# DECODER0_MSVDX_VEC_VC1 register map
Vendor: Texas Instruments
Peripheral module from a debugger description file (folder J7ES).
Registers are 32-bit, read-write, reset 0x0 unless marked. A register's access mark holds for its fields unless they carry their own. Offsets are as the file gives them; lines under a group give offsets from that group; [hi:lo] are bit positions; {n}, {i} and the like mark numbered series; 'fields as' and 'values as' point back to an identical list; <NAME> marks a mode.

## DECODER0_MSVDX_VEC_VC1
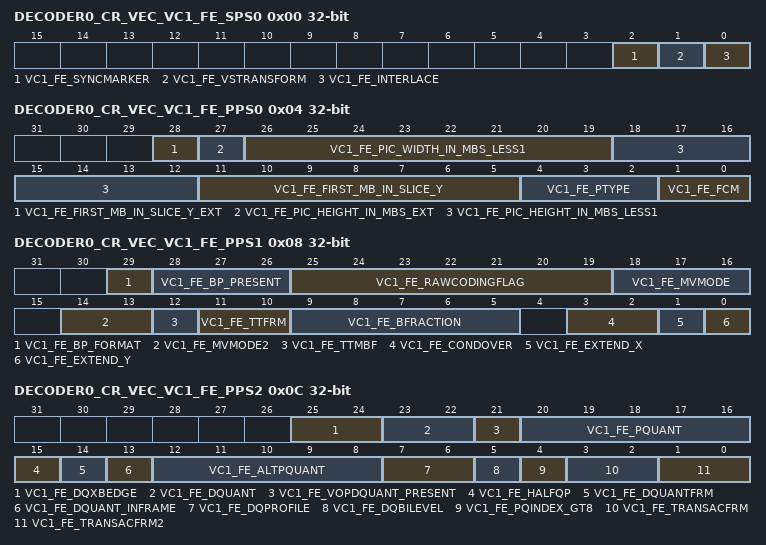
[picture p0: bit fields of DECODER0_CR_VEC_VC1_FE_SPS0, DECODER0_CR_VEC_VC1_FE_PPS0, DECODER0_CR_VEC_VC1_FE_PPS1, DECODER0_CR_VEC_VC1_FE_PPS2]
0x00 DECODER0_CR_VEC_VC1_FE_SPS0
  [2] VC1_FE_SYNCMARKER — Syncmarker Flag
  [1] VC1_FE_VSTRANSFORM — Variable Sized Transform Flag
  [0] VC1_FE_INTERLACE — Interlace Content [INTERLACE] [1 bit]
0x04 DECODER0_CR_VEC_VC1_FE_PPS0
  [28] VC1_FE_FIRST_MB_IN_SLICE_Y_EXT — Extension to VC1_FE_FIRST_MB_IN_SLICE_Y to allow for 4k x 4k resolution
  [27] VC1_FE_PIC_HEIGHT_IN_MBS_EXT — Extension to VC1_FE_PIC_HEIGHT_IN_MBS_LESS1 to allow for 4k x 4k resolution
  [26:19] VC1_FE_PIC_WIDTH_IN_MBS_LESS1 — of MBs less 1 across the width of the picture
  [18:12] VC1_FE_PIC_HEIGHT_IN_MBS_LESS1 — Number of MBs less 1 along the height of the picture [field or frame]
  [11:5] VC1_FE_FIRST_MB_IN_SLICE_Y — Slice Address
  [4:2] VC1_FE_PTYPE — Picture Type [PTYPE] [Variable size]
  [1:0] VC1_FE_FCM — Frame Coding Mode
0x08 DECODER0_CR_VEC_VC1_FE_PPS1
  [29] VC1_FE_BP_FORMAT — BP format in memory
  [28:26] VC1_FE_BP_PRESENT — Vector that indicates whether a given bitplane is present in the picture
  [25:19] VC1_FE_RAWCODINGFLAG — Vector that indicates whether a given bitplane is coded in raw mode
  [18:16] VC1_FE_MVMODE — Motion Vector Mode
  [14:13] VC1_FE_MVMODE2 — Motion Vector Mode 2
  [12] VC1_FE_TTMBF — Macroblock-level Transform Type Flag
  [11:10] VC1_FE_TTFRM — Frame-level Transform Type
  [9:5] VC1_FE_BFRACTION — Picture Fraction
  [3:2] VC1_FE_CONDOVER — Conditional Overlap Flag
  [1] VC1_FE_EXTEND_X — Extended Horizontal Differential Motion Vector Range Flag
  [0] VC1_FE_EXTEND_Y — Extended Vertical Differential Motion Vector Range Flag
0x0C DECODER0_CR_VEC_VC1_FE_PPS2
  [25:24] VC1_FE_DQXBEDGE — DQSBEDGE or DQDBEDGE, only one is present at any given instance
  [23:22] VC1_FE_DQUANT — Macroblock Quantization Flag [DQUANT]
  [21] VC1_FE_VOPDQUANT_PRESENT — Indicates whether MB Quantisation is used
  [20:16] VC1_FE_PQUANT — Picture Quantizer Scale [PQUANT]
  [15] VC1_FE_HALFQP — Half QP Step
  [14] VC1_FE_DQUANTFRM — Differential Quantizer Frame
  [13] VC1_FE_DQUANT_INFRAME — Indicates if quantizer can vary between the macroblocks of a frame.
  [12:8] VC1_FE_ALTPQUANT — Alternative Picture quantizer scale, defined by VOPDQUANT parameters, shall be applied to specific areas of the picture [in the same manner as PQUANT] when DQUANTFRM is set
  [7:6] VC1_FE_DQPROFILE — Differential Quantizer Profile [DQPROFILE] [2 bits]
  [5] VC1_FE_DQBILEVEL — Differential Quantizer Binary Level [DQBILEVEL] [1 bit]
  [4] VC1_FE_PQINDEX_GT8 — Flag to represent whether PQINDEX [described below] is greater than 8
  [3:2] VC1_FE_TRANSACFRM — Frame-level Transform AC Coding Set Index
  [1:0] VC1_FE_TRANSACFRM2 — Frame-level Transform AC Table-2 Index
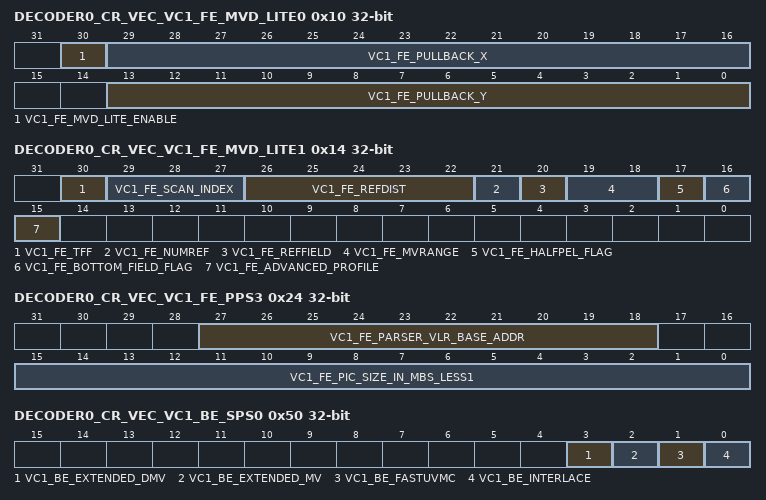
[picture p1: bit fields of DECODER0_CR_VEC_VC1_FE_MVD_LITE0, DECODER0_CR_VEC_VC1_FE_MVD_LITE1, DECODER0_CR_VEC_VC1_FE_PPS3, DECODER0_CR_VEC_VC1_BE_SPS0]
0x10 DECODER0_CR_VEC_VC1_FE_MVD_LITE0
  [30] VC1_FE_MVD_LITE_ENABLE — Flag to indicate whether MVD Lite is to be enabled
  [29:16] VC1_FE_PULLBACK_X — X value for Pullback
  [13:0] VC1_FE_PULLBACK_Y — Y value for Pullback
0x14 DECODER0_CR_VEC_VC1_FE_MVD_LITE1
  [30] VC1_FE_TFF — Top field first indicator
  [29:27] VC1_FE_SCAN_INDEX — Indicates picture type and profile for Inverse Scan to select the set of scan tables to use
  [26:22] VC1_FE_REFDIST — P Reference Distance [REFDIST]
  [21] VC1_FE_NUMREF — Number of Reference Pictures [NUMREF] [1 bit]
  [20] VC1_FE_REFFIELD — Reference Field Picture Indicator [REFFIELD] [1 bit]
  [19:18] VC1_FE_MVRANGE — Extended MV Range Flag [MVRANGE] [Variable size]
  [17] VC1_FE_HALFPEL_FLAG — Indicates the precision used for the MVs in the picture
  [16] VC1_FE_BOTTOM_FIELD_FLAG — Signals bottom field of current picture
  [15] VC1_FE_ADVANCED_PROFILE — Advanced profile flag - needed to check whether end of data implies that there might be extra skipped macroblocks to generate
0x18 DECODER0_CR_VEC_VC1_FE_BITPLANES_BASE_ADDR0
  [31:12] VC1_FE_BITPLANES_BASE_ADDR0 — Base address in the System Memory of Bitplane 0.
0x1C DECODER0_CR_VEC_VC1_FE_BITPLANES_BASE_ADDR1
  [31:12] VC1_FE_BITPLANES_BASE_ADDR1 — Base address in the System RAM of the Bitplane 1.
0x20 DECODER0_CR_VEC_VC1_FE_BITPLANES_BASE_ADDR2
  [31:12] VC1_FE_BITPLANES_BASE_ADDR2 — Base address in the System RAM of the Bitplane 2.
0x24 DECODER0_CR_VEC_VC1_FE_PPS3
  [27:18] VC1_FE_PARSER_VLR_BASE_ADDR — Base address pointer within VEC Local RAM used by VC-1 or MVD-lite or VC-1 bitplane parser.
  [15:0] VC1_FE_PIC_SIZE_IN_MBS_LESS1 — Size of picture in MBs less 1.
0x50 DECODER0_CR_VEC_VC1_BE_SPS0
  [3] VC1_BE_EXTENDED_DMV — Extended Differential Motion Vector Range Flag
  [2] VC1_BE_EXTENDED_MV — Extended Motion Vector Flag
  [1] VC1_BE_FASTUVMC — Fast UV Motion Compensation Flag
  [0] VC1_BE_INTERLACE — Interlace Content
0x54 DECODER0_CR_VEC_VC1_BE_SPS1
  [7:0] VC1_BE_PIC_HEIGHT_IN_MBS_LESS1 — of MBs less 1 along the height of the picture [field or frame]
0x58 DECODER0_CR_VEC_VC1_BE_SPS2
  [7:0] VC1_BE_PIC_WIDTH_IN_MBS_LESS1 — of MBs less 1 across the width of the picture
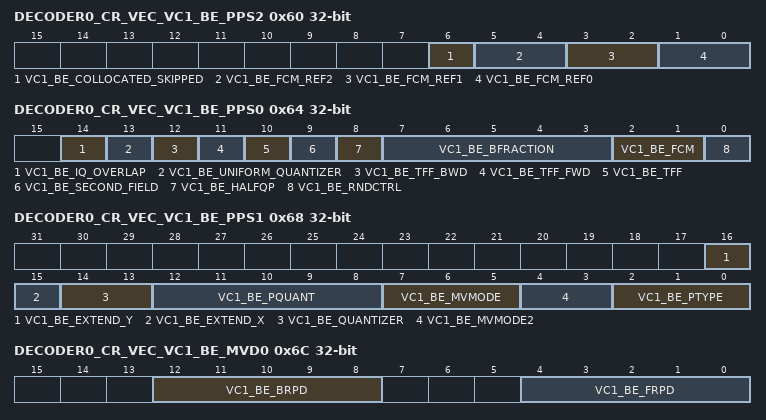
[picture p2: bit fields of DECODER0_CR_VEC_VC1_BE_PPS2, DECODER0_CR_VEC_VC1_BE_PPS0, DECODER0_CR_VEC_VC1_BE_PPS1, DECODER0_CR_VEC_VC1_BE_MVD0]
0x60 DECODER0_CR_VEC_VC1_BE_PPS2
  [6] VC1_BE_COLLOCATED_SKIPPED — Flag to indicate whether to use 0 collocated MVs
  [5:4] VC1_BE_FCM_REF2 — Frame Coding Mode for 3rd most recent reference picture
  [3:2] VC1_BE_FCM_REF1 — Frame Coding Mode for 2nd most recent reference picture
  [1:0] VC1_BE_FCM_REF0 — Frame Coding Mode for most recent reference picture
0x64 DECODER0_CR_VEC_VC1_BE_PPS0
  [14] VC1_BE_IQ_OVERLAP — If [picture_is_B OR CONDITIONAL_OVERLAP == 0 ] return 0
  [13] VC1_BE_UNIFORM_QUANTIZER — Indicates whether a uniform quantizer is used to inverse quantize block pixel data
  [12] VC1_BE_TFF_BWD — Indicates wether the top field was encoded first in the bitstream for the backward reference frame
  [11] VC1_BE_TFF_FWD — Indicates wether the top field was encoded first in the bitstream for the forward reference frame
  [10] VC1_BE_TFF — Top Field First
  [9] VC1_BE_SECOND_FIELD — Indicates whether the current field is the first or second to be decoded
  [8] VC1_BE_HALFQP — Half QP Step
  [7:3] VC1_BE_BFRACTION — B Picture Fraction
  [2:1] VC1_BE_FCM — Frame Coding Mode
  [0] VC1_BE_RNDCTRL — Rounding Control Bit
0x68 DECODER0_CR_VEC_VC1_BE_PPS1
  [16] VC1_BE_EXTEND_Y — Extended Vertical Differential Motion Vector Range Flag
  [15] VC1_BE_EXTEND_X — Extended Horizontal Differential Motion Vector Range
  [14:13] VC1_BE_QUANTIZER — Quantizer specifier at the picture layer
  [12:8] VC1_BE_PQUANT — Picture Quantizer Scale [PQUANT]
  [7:5] VC1_BE_MVMODE — Motion Vector Mode
  [4:3] VC1_BE_MVMODE2 — Motion Vector Mode 2
  [2:0] VC1_BE_PTYPE — Picture Type [PTYPE] [Variable size]
0x6C DECODER0_CR_VEC_VC1_BE_MVD0
  [12:8] VC1_BE_BRPD — Backward Reference Picture Distance
  [4:0] VC1_BE_FRPD — Forward Reference Picture Distance
0x70 DECODER0_CR_VEC_VC1_BE_MVD1
  [10:0] VC1_BE_SCALEFACTOR — SCALEFACTOR used for direct mode temporal scaling of motion vectors
0x74 DECODER0_CR_VEC_VC1_BE_MVD2
  [13:0] VC1_BE_PULLBACK_X — MV Pullback parameter for X dimension
0x78 DECODER0_CR_VEC_VC1_BE_MVD3
  [13:0] VC1_BE_PULLBACK_Y — MV Pullback parameter for Y dimension
0x7C DECODER0_CR_VEC_VC1_BE_MVD4
  [7:0] VC1_BE_FIRST_MB_IN_SLICE_Y — Slice Address
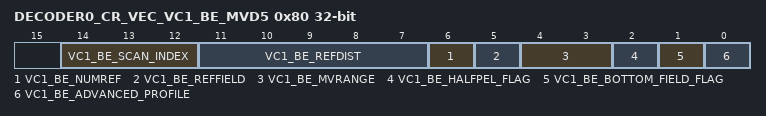
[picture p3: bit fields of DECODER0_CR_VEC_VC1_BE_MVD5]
0x80 DECODER0_CR_VEC_VC1_BE_MVD5
  [14:12] VC1_BE_SCAN_INDEX — Indicates picture type and profile for Inverse Scan to select the set of scan tables to use
  [11:7] VC1_BE_REFDIST — P Reference Distance
  [6] VC1_BE_NUMREF — Number of Reference Pictures
  [5] VC1_BE_REFFIELD — Reference Field Picture Indicator
  [4:3] VC1_BE_MVRANGE — Extended MV Range Flag
  [2] VC1_BE_HALFPEL_FLAG — Indicates the precision used for the MVs in the picture
  [1] VC1_BE_BOTTOM_FIELD_FLAG — Signals bottom field of current picture
  [0] VC1_BE_ADVANCED_PROFILE — Advanced profile flag
0xEC DECODER0_CR_VEC_VC1_BE_PARAM_BASE_ADDR
  [31:12] VC1_BE_PARAM_BASE_ADDRESS — address for the memory to store MB parameters
0xF8 DECODER0_CR_VEC_VC1_BE_COLPARAM_BASE_ADDR
  [31:12] VC1_BE_COLPARAM_BASE_ADDRESS — address for the memory to access co-located MB parameters
0x100 DECODER0_CR_VEC_VC1_BP_READ
  [15:0] VC1_BP_READ — This is the read only register for transfering bitplane data from the CABAC RAM to the host memory.
